# iostr736 register map
Registers are 16-bit, access not given, no defined reset value unless marked. A register's access mark holds for its fields unless they carry their own. Addresses are absolute; registers are grouped by the start of their names; [hi:lo] are bit positions; {n}, {i} and the like mark numbered series.

## BSPI1
0xFFFFDC00 BSPI1_RXR
0xFFFFDC04 BSPI1_TXR
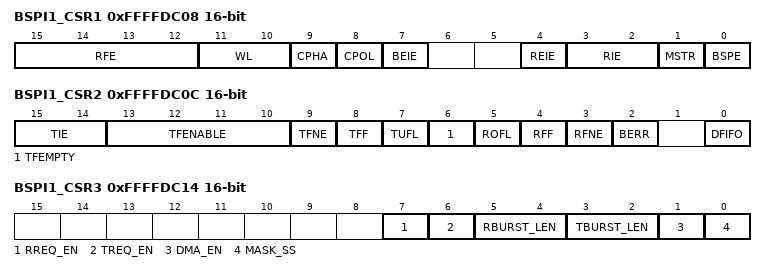
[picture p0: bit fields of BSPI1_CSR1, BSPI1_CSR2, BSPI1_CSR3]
0xFFFFDC08 BSPI1_CSR1
  [15:12] RFE, [11:10] WL, [9] CPHA, [8] CPOL, [7] BEIE, [4] REIE, [3:2] RIE, [1] MSTR, [0] BSPE
0xFFFFDC0C BSPI1_CSR2
  [15:14] TIE, [13:10] TFENABLE, [9] TFNE, [8] TFF, [7] TUFL, [6] TFEMPTY, [5] ROFL, [4] RFF, [3] RFNE, [2] BERR, [0] DFIFO
0xFFFFDC10 BSPI1_CLK
  [7:0] DIV
0xFFFFDC14 BSPI1_CSR3
  [7] RREQ_EN, [6] TREQ_EN, [5:4] RBURST_LEN, [3:2] TBURST_LEN, [1] DMA_EN, [0] MASK_SS

## BSPI2
0xFFFFE000 BSPI2_RXR
0xFFFFE004 BSPI2_TXR
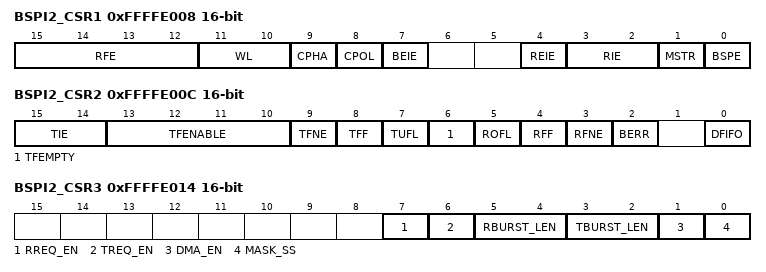
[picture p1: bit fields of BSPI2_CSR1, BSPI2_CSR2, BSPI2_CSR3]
0xFFFFE008 BSPI2_CSR1
  [15:12] RFE, [11:10] WL, [9] CPHA, [8] CPOL, [7] BEIE, [4] REIE, [3:2] RIE, [1] MSTR, [0] BSPE
0xFFFFE00C BSPI2_CSR2
  [15:14] TIE, [13:10] TFENABLE, [9] TFNE, [8] TFF, [7] TUFL, [6] TFEMPTY, [5] ROFL, [4] RFF, [3] RFNE, [2] BERR, [0] DFIFO
0xFFFFE010 BSPI2_CLK
  [7:0] DIV
0xFFFFE014 BSPI2_CSR3
  [7] RREQ_EN, [6] TREQ_EN, [5:4] RBURST_LEN, [3:2] TBURST_LEN, [1] DMA_EN, [0] MASK_SS

## TIM2
0xFFFFE400 TIM2_ICAR
0xFFFFE404 TIM2_ICBR
0xFFFFE408 TIM2_OCAR
0xFFFFE40C TIM2_OCBR
0xFFFFE410 TIM2_CNTR
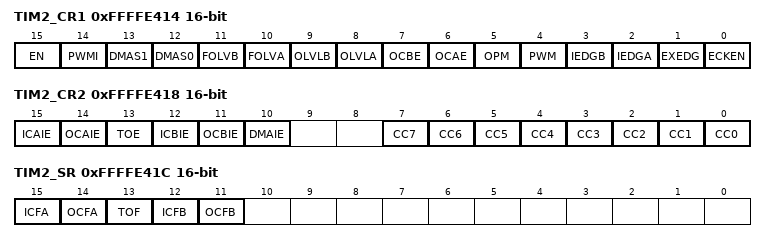
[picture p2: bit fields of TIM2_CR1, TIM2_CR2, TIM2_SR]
0xFFFFE414 TIM2_CR1
  [15] EN, [14] PWMI, [13] DMAS1, [12] DMAS0, [11] FOLVB, [10] FOLVA, [9] OLVLB, [8] OLVLA, [7] OCBE, [6] OCAE, [5] OPM, [4] PWM, [3] IEDGB, [2] IEDGA, [1] EXEDG, [0] ECKEN
0xFFFFE418 TIM2_CR2
  [15] ICAIE, [14] OCAIE, [13] TOE, [12] ICBIE, [11] OCBIE, [10] DMAIE, [n] CC{n} (n=0..7)
0xFFFFE41C TIM2_SR
  [15] ICFA, [14] OCFA, [13] TOF, [12] ICFB, [11] OCFB

## TIM3
0xFFFFE800 TIM3_ICAR
0xFFFFE804 TIM3_ICBR
0xFFFFE808 TIM3_OCAR
0xFFFFE80C TIM3_OCBR
0xFFFFE810 TIM3_CNTR
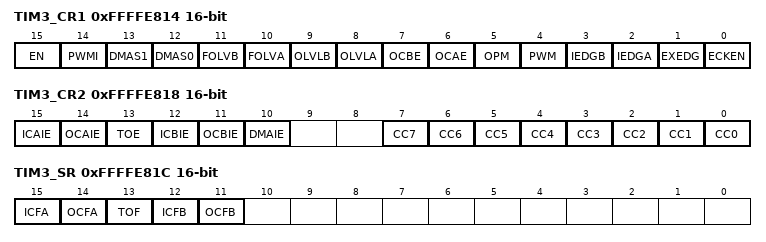
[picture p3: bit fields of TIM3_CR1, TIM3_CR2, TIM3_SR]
0xFFFFE814 TIM3_CR1
  [15] EN, [14] PWMI, [13] DMAS1, [12] DMAS0, [11] FOLVB, [10] FOLVA, [9] OLVLB, [8] OLVLA, [7] OCBE, [6] OCAE, [5] OPM, [4] PWM, [3] IEDGB, [2] IEDGA, [1] EXEDG, [0] ECKEN
0xFFFFE818 TIM3_CR2
  [15] ICAIE, [14] OCAIE, [13] TOE, [12] ICBIE, [11] OCBIE, [10] DMAIE, [n] CC{n} (n=0..7)
0xFFFFE81C TIM3_SR
  [15] ICFA, [14] OCFA, [13] TOF, [12] ICFB, [11] OCFB

## TIM4
0xFFFFEC00 TIM4_ICAR
0xFFFFEC04 TIM4_ICBR
0xFFFFEC08 TIM4_OCAR
0xFFFFEC0C TIM4_OCBR
0xFFFFEC10 TIM4_CNTR
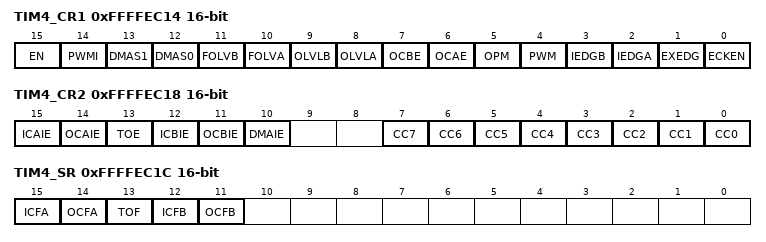
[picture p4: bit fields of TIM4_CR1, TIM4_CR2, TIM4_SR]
0xFFFFEC14 TIM4_CR1
  [15] EN, [14] PWMI, [13] DMAS1, [12] DMAS0, [11] FOLVB, [10] FOLVA, [9] OLVLB, [8] OLVLA, [7] OCBE, [6] OCAE, [5] OPM, [4] PWM, [3] IEDGB, [2] IEDGA, [1] EXEDG, [0] ECKEN
0xFFFFEC18 TIM4_CR2
  [15] ICAIE, [14] OCAIE, [13] TOE, [12] ICBIE, [11] OCBIE, [10] DMAIE, [n] CC{n} (n=0..7)
0xFFFFEC1C TIM4_SR
  [15] ICFA, [14] OCFA, [13] TOF, [12] ICFB, [11] OCFB

## DMA0
{0xFFFFF000+0x40*i} DMA0_SOURCEL{i} (i=0..3)
{0xFFFFF004+0x40*i} DMA0_SOURCEH{i} (i=0..3)
{0xFFFFF008+0x40*i} DMA0_DESTL{i} (i=0..3)
{0xFFFFF00C+0x40*i} DMA0_DESTH{i} (i=0..3)
{0xFFFFF010+0x40*i} DMA0_MAX{i} (i=0..3)
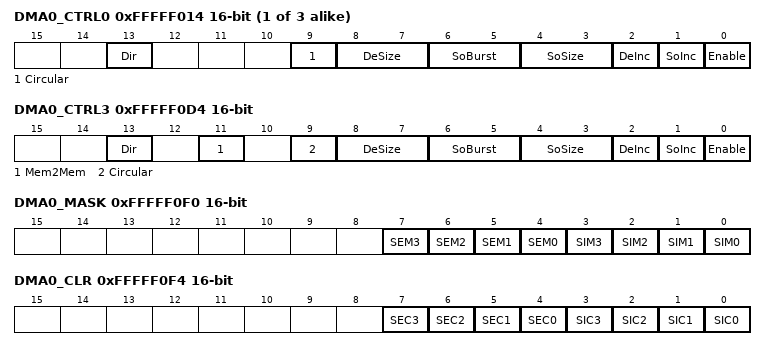
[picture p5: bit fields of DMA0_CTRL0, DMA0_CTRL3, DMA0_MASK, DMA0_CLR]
{0xFFFFF014+0x40*i} DMA0_CTRL{i} (i=0..2)
  [13] Dir, [9] Circular, [8:7] DeSize, [6:5] SoBurst, [4:3] SoSize, [2] DeInc, [1] SoInc, [0] Enable
{0xFFFFF018+0x40*i} DMA0_SOCURRH{i} (i=0..3)
{0xFFFFF01C+0x40*i} DMA0_SOCURRL{i} (i=0..3)
{0xFFFFF020+0x40*i} DMA0_DECURRH{i} (i=0..3)
{0xFFFFF024+0x40*i} DMA0_DECURRL{i} (i=0..3)
{0xFFFFF028+0x40*i} DMA0_TCNT{i} (i=0..3)
{0xFFFFF02C+0x40*i} DMA0_LUBuff{i} (i=0..3)
0xFFFFF0D4 DMA0_CTRL3
  [13] Dir, [11] Mem2Mem, [9] Circular, [8:7] DeSize, [6:5] SoBurst, [4:3] SoSize, [2] DeInc, [1] SoInc, [0] Enable
0xFFFFF0F0 DMA0_MASK
  [n+4] SEM{n} (n=0..3), [n] SIM{n} (n=0..3)
0xFFFFF0F4 DMA0_CLR
  [n+4] SEC{n} (n=0..3), [n] SIC{n} (n=0..3)
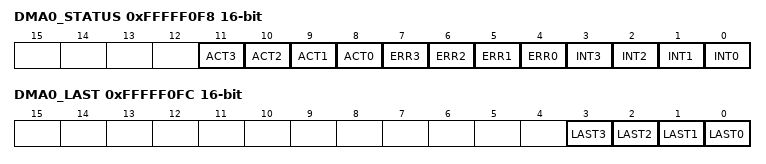
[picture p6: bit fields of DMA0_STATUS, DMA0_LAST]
0xFFFFF0F8 DMA0_STATUS
  [n+8] ACT{n} (n=0..3), [n+4] ERR{n} (n=0..3), [n] INT{n} (n=0..3)
0xFFFFF0FC DMA0_LAST
  [n] LAST{n} (n=0..3)

## DMA1
{0xFFFFF100+0x40*i} DMA1_SOURCEL{i} (i=0..3)
{0xFFFFF104+0x40*i} DMA1_SOURCEH{i} (i=0..3)
{0xFFFFF108+0x40*i} DMA1_DESTL{i} (i=0..3)
{0xFFFFF10C+0x40*i} DMA1_DESTH{i} (i=0..3)
{0xFFFFF110+0x40*i} DMA1_MAX{i} (i=0..3)
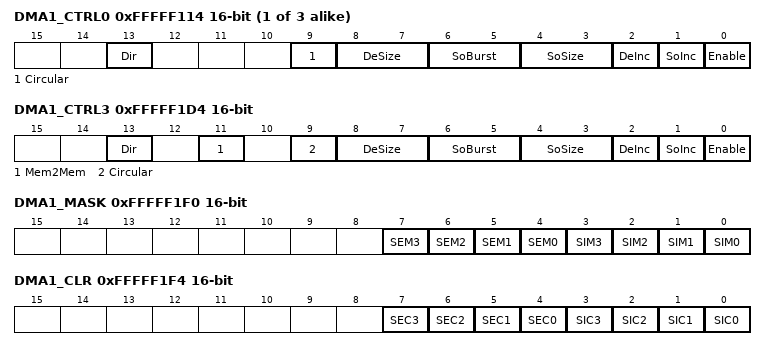
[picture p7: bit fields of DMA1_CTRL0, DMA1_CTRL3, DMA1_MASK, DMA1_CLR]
{0xFFFFF114+0x40*i} DMA1_CTRL{i} (i=0..2)
  [13] Dir, [9] Circular, [8:7] DeSize, [6:5] SoBurst, [4:3] SoSize, [2] DeInc, [1] SoInc, [0] Enable
{0xFFFFF118+0x40*i} DMA1_SOCURRH{i} (i=0..3)
{0xFFFFF11C+0x40*i} DMA1_SOCURRL{i} (i=0..3)
{0xFFFFF120+0x40*i} DMA1_DECURRH{i} (i=0..3)
{0xFFFFF124+0x40*i} DMA1_DECURRL{i} (i=0..3)
{0xFFFFF128+0x40*i} DMA1_TCNT{i} (i=0..3)
{0xFFFFF12C+0x40*i} DMA1_LUBuff{i} (i=0..3)
0xFFFFF1D4 DMA1_CTRL3
  [13] Dir, [11] Mem2Mem, [9] Circular, [8:7] DeSize, [6:5] SoBurst, [4:3] SoSize, [2] DeInc, [1] SoInc, [0] Enable
0xFFFFF1F0 DMA1_MASK
  [n+4] SEM{n} (n=0..3), [n] SIM{n} (n=0..3)
0xFFFFF1F4 DMA1_CLR
  [n+4] SEC{n} (n=0..3), [n] SIC{n} (n=0..3)
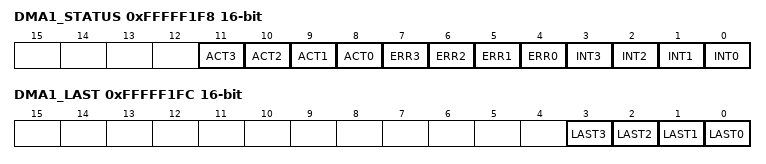
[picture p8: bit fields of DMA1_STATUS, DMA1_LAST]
0xFFFFF1F8 DMA1_STATUS
  [n+8] ACT{n} (n=0..3), [n+4] ERR{n} (n=0..3), [n] INT{n} (n=0..3)
0xFFFFF1FC DMA1_LAST
  [n] LAST{n} (n=0..3)

## DMA2
{0xFFFFF200+0x40*i} DMA2_SOURCEL{i} (i=0..3)
{0xFFFFF204+0x40*i} DMA2_SOURCEH{i} (i=0..3)
{0xFFFFF208+0x40*i} DMA2_DESTL{i} (i=0..3)
{0xFFFFF20C+0x40*i} DMA2_DESTH{i} (i=0..3)
{0xFFFFF210+0x40*i} DMA2_MAX{i} (i=0..3)
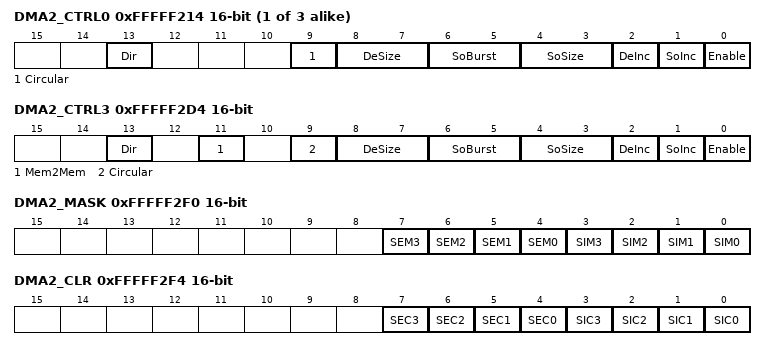
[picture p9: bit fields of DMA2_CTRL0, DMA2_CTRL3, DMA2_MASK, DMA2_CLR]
{0xFFFFF214+0x40*i} DMA2_CTRL{i} (i=0..2)
  [13] Dir, [9] Circular, [8:7] DeSize, [6:5] SoBurst, [4:3] SoSize, [2] DeInc, [1] SoInc, [0] Enable
{0xFFFFF218+0x40*i} DMA2_SOCURRH{i} (i=0..3)
{0xFFFFF21C+0x40*i} DMA2_SOCURRL{i} (i=0..3)
{0xFFFFF220+0x40*i} DMA2_DECURRH{i} (i=0..3)
{0xFFFFF224+0x40*i} DMA2_DECURRL{i} (i=0..3)
{0xFFFFF228+0x40*i} DMA2_TCNT{i} (i=0..3)
{0xFFFFF22C+0x40*i} DMA2_LUBuff{i} (i=0..3)
0xFFFFF2D4 DMA2_CTRL3
  [13] Dir, [11] Mem2Mem, [9] Circular, [8:7] DeSize, [6:5] SoBurst, [4:3] SoSize, [2] DeInc, [1] SoInc, [0] Enable
0xFFFFF2F0 DMA2_MASK
  [n+4] SEM{n} (n=0..3), [n] SIM{n} (n=0..3)
0xFFFFF2F4 DMA2_CLR
  [n+4] SEC{n} (n=0..3), [n] SIC{n} (n=0..3)
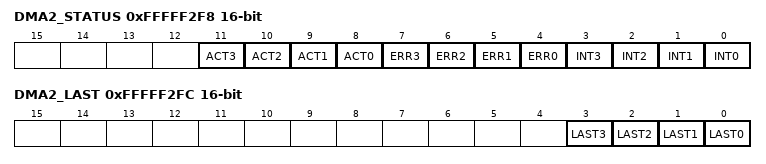
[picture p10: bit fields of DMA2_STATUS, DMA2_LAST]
0xFFFFF2F8 DMA2_STATUS
  [n+8] ACT{n} (n=0..3), [n+4] ERR{n} (n=0..3), [n] INT{n} (n=0..3)
0xFFFFF2FC DMA2_LAST
  [n] LAST{n} (n=0..3)

## DMA3
{0xFFFFF300+0x40*i} DMA3_SOURCEL{i} (i=0..3)
{0xFFFFF304+0x40*i} DMA3_SOURCEH{i} (i=0..3)
{0xFFFFF308+0x40*i} DMA3_DESTL{i} (i=0..3)
{0xFFFFF30C+0x40*i} DMA3_DESTH{i} (i=0..3)
{0xFFFFF310+0x40*i} DMA3_MAX{i} (i=0..3)
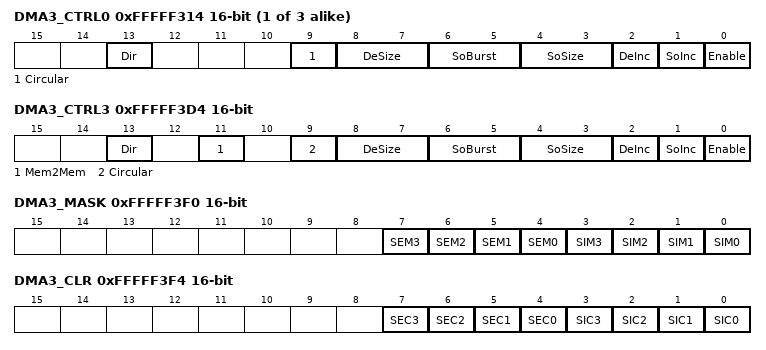
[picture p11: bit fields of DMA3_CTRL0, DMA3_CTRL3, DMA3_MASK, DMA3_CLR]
{0xFFFFF314+0x40*i} DMA3_CTRL{i} (i=0..2)
  [13] Dir, [9] Circular, [8:7] DeSize, [6:5] SoBurst, [4:3] SoSize, [2] DeInc, [1] SoInc, [0] Enable
{0xFFFFF318+0x40*i} DMA3_SOCURRH{i} (i=0..3)
{0xFFFFF31C+0x40*i} DMA3_SOCURRL{i} (i=0..3)
{0xFFFFF320+0x40*i} DMA3_DECURRH{i} (i=0..3)
{0xFFFFF324+0x40*i} DMA3_DECURRL{i} (i=0..3)
{0xFFFFF328+0x40*i} DMA3_TCNT{i} (i=0..3)
{0xFFFFF32C+0x40*i} DMA3_LUBuff{i} (i=0..3)
0xFFFFF3D4 DMA3_CTRL3
  [13] Dir, [11] Mem2Mem, [9] Circular, [8:7] DeSize, [6:5] SoBurst, [4:3] SoSize, [2] DeInc, [1] SoInc, [0] Enable
0xFFFFF3F0 DMA3_MASK
  [n+4] SEM{n} (n=0..3), [n] SIM{n} (n=0..3)
0xFFFFF3F4 DMA3_CLR
  [n+4] SEC{n} (n=0..3), [n] SIC{n} (n=0..3)
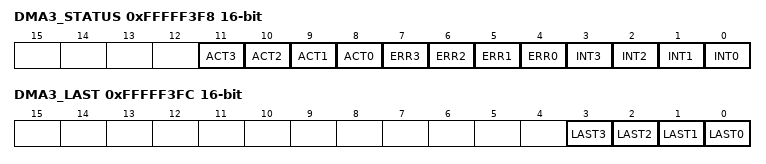
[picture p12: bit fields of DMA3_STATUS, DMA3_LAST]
0xFFFFF3F8 DMA3_STATUS
  [n+8] ACT{n} (n=0..3), [n+4] ERR{n} (n=0..3), [n] INT{n} (n=0..3)
0xFFFFF3FC DMA3_LAST
  [n] LAST{n} (n=0..3)

## RTC
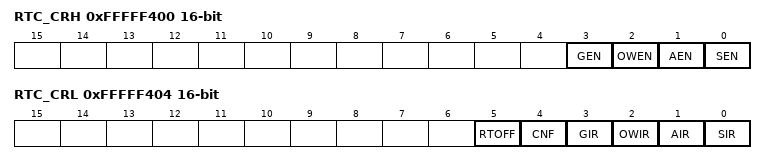
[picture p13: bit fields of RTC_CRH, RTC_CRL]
0xFFFFF400 RTC_CRH
  [3] GEN, [2] OWEN, [1] AEN, [0] SEN
0xFFFFF404 RTC_CRL
  [5] RTOFF, [4] CNF, [3] GIR, [2] OWIR, [1] AIR, [0] SIR
0xFFFFF408 RTC_PRLH
  [3:0] PRSL
0xFFFFF40C RTC_PRLL
0xFFFFF410 RTC_DIVH
  [3:0] DIV
0xFFFFF414 RTC_DIVL
0xFFFFF418 RTC_CNTH
0xFFFFF41C RTC_CNTL
0xFFFFF420 RTC_ALRH
0xFFFFF424 RTC_ALRL

## ADC
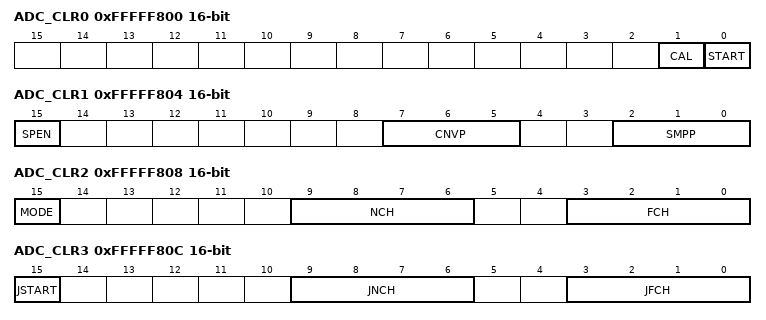
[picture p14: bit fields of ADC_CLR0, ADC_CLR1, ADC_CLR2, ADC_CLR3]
0xFFFFF800 ADC_CLR0
  [1] CAL, [0] START
0xFFFFF804 ADC_CLR1
  [15] SPEN, [7:5] CNVP, [2:0] SMPP
0xFFFFF808 ADC_CLR2
  [15] MODE, [9:6] NCH, [3:0] FCH
0xFFFFF80C ADC_CLR3
  [15] JSTART, [9:6] JNCH, [3:0] JFCH
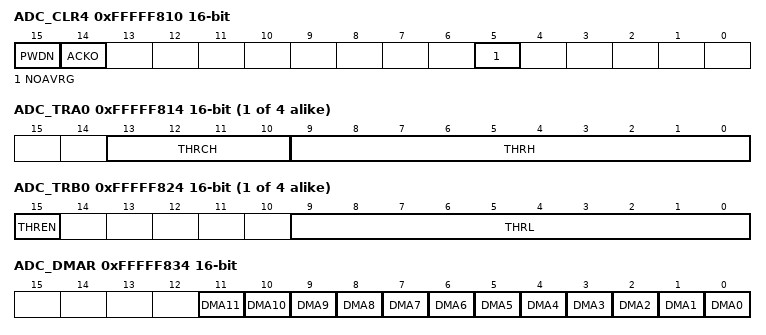
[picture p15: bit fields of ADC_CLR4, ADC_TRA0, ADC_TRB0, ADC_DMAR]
0xFFFFF810 ADC_CLR4
  [15] PWDN, [14] ACKO, [5] NOAVRG
{0xFFFFF814+4i} ADC_TRA{i} (i=0..3)
  [13:10] THRCH, [9:0] THRH
{0xFFFFF824+4i} ADC_TRB{i} (i=0..3)
  [15] THREN, [9:0] THRL
0xFFFFF834 ADC_DMAR
  [n] DMA{n} (n=0..11)
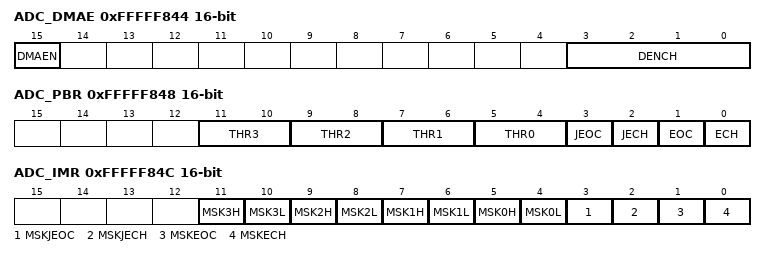
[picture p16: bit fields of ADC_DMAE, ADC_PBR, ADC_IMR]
0xFFFFF844 ADC_DMAE
  [15] DMAEN, [3:0] DENCH
0xFFFFF848 ADC_PBR
  [2n+5:2n+4] THR{n} (n=0..3), [3] JEOC, [2] JECH, [1] EOC, [0] ECH
0xFFFFF84C ADC_IMR
  [2n+5] MSK{n}H (n=0..3), [2n+4] MSK{n}L (n=0..3), [3] MSKJEOC, [2] MSKJECH, [1] MSKEOC, [0] MSKECH
{0xFFFFF850+4i} ADC_D{i} (i=0..11)
  [9:0] CDATA
